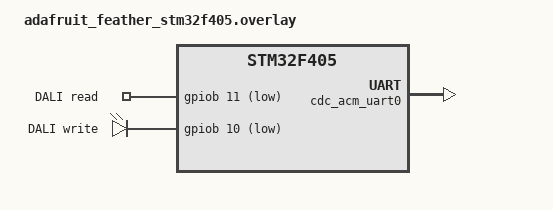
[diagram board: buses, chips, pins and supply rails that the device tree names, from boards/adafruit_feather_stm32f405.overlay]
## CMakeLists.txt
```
# SPDX-License-Identifier: Apache-2.0

cmake_minimum_required(VERSION 3.20.0)

find_package(Zephyr REQUIRED HINTS $ENV{ZEPHYR_BASE})
project(farm_light_control)

target_sources(app PRIVATE
	src/main.c
	src/dali.c
	)
```

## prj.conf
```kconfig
##################################################
## USB
##################################################
#
#CONFIG_USB_DEVICE_STACK=y
#CONFIG_USB_DEVICE_PRODUCT="zephyr_usb_logger"
#CONFIG_USB_DEVICE_PID=0x0004
#CONFIG_USB_DEVICE_INITIALIZE_AT_BOOT=n
#
##################################################
## LOGGING
##################################################
#
#CONFIG_SERIAL=y
#CONFIG_CONSOLE=y
#CONFIG_UART_CONSOLE=y
#CONFIG_UART_LINE_CTRL=y
#
#CONFIG_LOG=y
#CONFIG_LOG_MODE_IMMEDIATE=y

CONFIG_GPIO=y
```

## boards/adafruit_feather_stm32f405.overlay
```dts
/*
 * SPDX-License-Identifier: Apache-2.0
 * Copyright (c) 2023 RSA FG
 */

/ {
	chosen {
		/* zephyr,console = &cdc_acm_uart0; */
		/* zephyr,shell-uart = &cdc_acm_uart0; */
	};

	buttons {
		compatible = "gpio-keys";
		debounce-interval-ms = <250>;
		dali_rx: dali_rx {
			gpios = <&gpiob 11 GPIO_ACTIVE_LOW>;
			label = "DALI read";
		};
	};

	leds {
		compatible = "gpio-leds";
		dali_tx: dali_tx {
			gpios = <&gpiob 10 GPIO_ACTIVE_LOW>;
			label = "DALI write";
		};
	};
};

&zephyr_udc0 {
	cdc_acm_uart0: cdc_acm_uart0 {
		compatible = "zephyr,cdc-acm-uart";
	};
};
```

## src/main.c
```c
/*
 * Copyright (c) 2023 RSA FG
 *
 * SPDX-License-Identifier: Apache-2.0
 */

#include <zephyr/kernel.h>

#include <stdio.h>
#include <ctype.h>
#include <errno.h>

#include "dali.h"

#include <zephyr/logging/log.h>
LOG_MODULE_REGISTER(main, LOG_LEVEL_DBG);

int main(void)
{
	LOG_INF("starting application");

	while (1)
	{
		LOG_INF("switch off");
		dali_send_data(BROADCAST_C, OFF_C);
		k_sleep(K_SECONDS(1));

		LOG_INF("switch on");
		dali_send_data(BROADCAST_C, ON_C);
		k_sleep(K_SECONDS(1));
	}

	return 0;
}
```

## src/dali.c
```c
/*
 * Copyright (c) 2023 RSA FG
 *
 * SPDX-License-Identifier: Apache-2.0
 */

#include "dali.h"

#include <zephyr/kernel.h>
#include <zephyr/drivers/gpio.h>

#include <zephyr/logging/log.h>
LOG_MODULE_REGISTER(dali, LOG_LEVEL_DBG);

#define STOP_BITS_PERIOD K_USEC(5500)

static const struct gpio_dt_spec dali_tx = GPIO_DT_SPEC_GET(DT_NODELABEL(dali_tx), gpios);
static const struct gpio_dt_spec dali_rx = GPIO_DT_SPEC_GET(DT_NODELABEL(dali_rx), gpios);

#define HALF_BIT_PERIOD K_USEC(284)
#define QUARTER_BIT_PERIOD K_USEC(284 / 2)

#define DALI_WAIT K_MSEC(50)

#define FADE_ITERATIONS 20

static uint8_t addr;
static uint8_t command;

static uint16_t rx_buf;
static uint16_t rx_buf_rdy = 0;

static struct gpio_callback dali_cb_data;

static K_THREAD_STACK_DEFINE(dali_loop_worker_stack_area, 1024);
static struct k_thread dali_loop_worker_data;
static k_tid_t dali_loop_worker_tid = 0;

static void dali_write_bit_0(void)
{
        if (!gpio_is_ready_dt(&dali_tx)) {
		LOG_ERR("device not ready");
                return;
        }
        
	gpio_pin_configure_dt(&dali_tx, GPIO_OUTPUT_ACTIVE);
	k_sleep(HALF_BIT_PERIOD);
	gpio_pin_configure_dt(&dali_tx, GPIO_OUTPUT_INACTIVE);
	k_sleep(HALF_BIT_PERIOD);
}

static void dali_write_bit_1(void)
{
        if (!gpio_is_ready_dt(&dali_tx)) {
		LOG_ERR("device not ready");
                return;
        }
        
	gpio_pin_configure_dt(&dali_tx, GPIO_OUTPUT_INACTIVE);
	k_sleep(HALF_BIT_PERIOD);
	gpio_pin_configure_dt(&dali_tx, GPIO_OUTPUT_ACTIVE);
	k_sleep(HALF_BIT_PERIOD);
}

static void dali_write_idle(void)
{
	gpio_pin_configure_dt(&dali_tx, GPIO_OUTPUT_ACTIVE);
	k_sleep(STOP_BITS_PERIOD);
}

static void dali_write_byte(uint8_t data)
{
	uint8_t i = 0x80;

	for (i = 0x80; i > 0x00; i >>= 1)
	{
		if (data & i)
	       	{
			dali_write_bit_1();
		}
		else
		{
			dali_write_bit_0();
		}
	}
}

void dali_query(void)
{
	dali_send_data(BROADCAST_C, QUERY_STATUS);
}

void dali_on(void)
{
	dali_send_data(BROADCAST_C, ON_C);
}

void dali_off(void)
{
	dali_send_data(BROADCAST_C, OFF_C);
}

static void dali_loop_worker(void *p1, void *p2, void *p3)
{
	gpio_remove_callback(dali_rx.port, &dali_cb_data);
	dali_write_bit_1();
	dali_write_byte(*(uint8_t *)p1);
	dali_write_byte(*(uint8_t *)p2);
	dali_write_idle();
	gpio_add_callback(dali_rx.port, &dali_cb_data);

	dali_loop_worker_tid = 0;

        return;
}

void dali_send_data(uint8_t _addr, uint8_t _command)
{
	addr = _addr;
	command = _command;

	if (dali_loop_worker_tid > 0)
	{
		return;
	}

	dali_loop_worker_tid = k_thread_create(&dali_loop_worker_data,
                        dali_loop_worker_stack_area,
                        K_THREAD_STACK_SIZEOF(dali_loop_worker_stack_area),
                        dali_loop_worker,
                        &addr, &command, NULL,
                        -CONFIG_NUM_COOP_PRIORITIES, 0, K_NO_WAIT);
}

static void dali_receive(const struct device *dev, struct gpio_callback *cb,
		    uint32_t pins)
{
	static uint32_t last = 0;
	uint32_t now = k_cycle_get_32();
	uint32_t diff = now - last;

	static uint8_t received_half_bits = 0;
	static uint8_t last_bit = 1;

	if (diff > 200000)
       	{
		rx_buf = 0x00;
		rx_buf_rdy = 0;
		received_half_bits = 0;
		last_bit = 1;
	}
       	else if (diff > 105000)
	{
		rx_buf <<= 1;
		// long: bit shift
		last_bit = !last_bit;
		rx_buf |= last_bit;

		received_half_bits+=2;
		LOG_INF("long");
	}
	else
	{
		received_half_bits++;
		if (received_half_bits % 2 == 1)
		{
			rx_buf <<= 1;
			rx_buf |= last_bit;
		}
		// short: same bit
		LOG_INF("short");
	}

	if (received_half_bits >= 17)
	{
		rx_buf_rdy = 1;
		LOG_INF("received data: %hu", rx_buf & 0x00ff);
	}

	last = now;
}

int dali_receive_byte()
{
	int i;
	for (i = 0; i < 500; i++)
	{
		if (rx_buf_rdy == 1) {
			break;
		}
		k_sleep(K_MSEC(1));
	}

	if (i >= 500) {
		return -1;
	}

	rx_buf_rdy = 0;
	return rx_buf;
}

static int dali_initialize(void)
{
	int ret;

	if (!gpio_is_ready_dt(&dali_rx)) {
		LOG_ERR("Error: dali device %s is not ready\n",
		       dali_rx.port->name);
		return 0;
	}

	ret = gpio_pin_configure_dt(&dali_rx, GPIO_INPUT | GPIO_ACTIVE_LOW);
	if (ret != 0) {
		LOG_ERR("Error %d: failed to configure %s pin %d\n",
		       ret, dali_rx.port->name, dali_rx.pin);
		return 0;
	}

	ret = gpio_pin_interrupt_configure_dt(&dali_rx,
					      GPIO_INT_EDGE_BOTH);
	if (ret != 0) {
		LOG_ERR("Error %d: failed to configure interrupt on %s pin %d\n",
			ret, dali_rx.port->name, dali_rx.pin);
		return 0;
	}

	gpio_init_callback(&dali_cb_data, dali_receive, BIT(dali_rx.pin));
	gpio_add_callback(dali_rx.port, &dali_cb_data);

	LOG_INF("successfully initialized");
	return 0;
}

SYS_INIT(dali_initialize, APPLICATION, CONFIG_APPLICATION_INIT_PRIORITY);
```

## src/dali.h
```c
#ifndef DALI_H 
#define DALI_H 

#define BROADCAST_C  0xff
#define BROADCAST_P  0xfe

#define OFF_C        0x00
#define ON_C         0x05
#define QUERY_STATUS 0x90

#define DALI_C_INITIALIZE 0xa5
#define DALI_C_RANDOMIZE  0xa7
#define DALI_C_COMPARE    0xa9
#define DALI_C_WITHDRAW   0xab
#define DALI_C_PING       0xad
#define DALI_C_RESET      0x20

#include <zephyr/kernel.h>

int dali_receive_byte();
void dali_send_data(uint8_t _addr, uint8_t _command);

#endif /* DALI_H */
```

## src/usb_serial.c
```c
/*
 * Copyright (c) 2016 Intel Corporation.
 *
 * SPDX-License-Identifier: Apache-2.0
 */

#include <zephyr/kernel.h>
#include <zephyr/usb/usb_device.h>
#include <zephyr/usb/usbd.h>
#include <zephyr/drivers/uart.h>

#include <zephyr/linker/sections.h>
#include <errno.h>
#include <stdio.h>

#include <zephyr/logging/log.h>
LOG_MODULE_REGISTER(usb_serial, LOG_LEVEL_DBG);

BUILD_ASSERT(DT_NODE_HAS_COMPAT(DT_CHOSEN(zephyr_console), zephyr_cdc_acm_uart),
	     "Console device is not ACM CDC UART device");

#if defined(CONFIG_USB_DEVICE_STACK_NEXT)
USBD_CONFIGURATION_DEFINE(config_1,
			  USB_SCD_SELF_POWERED,
			  200);

USBD_DESC_LANG_DEFINE(sample_lang);
USBD_DESC_MANUFACTURER_DEFINE(sample_mfr, "ZEPHYR");
USBD_DESC_PRODUCT_DEFINE(sample_product, "Zephyr USBD ACM console");
USBD_DESC_SERIAL_NUMBER_DEFINE(sample_sn, "0123456789ABCDEF");

USBD_DEVICE_DEFINE(sample_usbd,
		   DEVICE_DT_GET(DT_NODELABEL(zephyr_udc0)),
		   0x2fe3, 0x0001);

static int enable_usb_device_next(void)
{
	int err;

	err = usbd_add_descriptor(&sample_usbd, &sample_lang);
	if (err) {
		return err;
	}

	err = usbd_add_descriptor(&sample_usbd, &sample_mfr);
	if (err) {
		return err;
	}

	err = usbd_add_descriptor(&sample_usbd, &sample_product);
	if (err) {
		return err;
	}

	err = usbd_add_descriptor(&sample_usbd, &sample_sn);
	if (err) {
		return err;
	}

	err = usbd_add_configuration(&sample_usbd, &config_1);
	if (err) {
		return err;
	}

	err = usbd_register_class(&sample_usbd, "cdc_acm_0", 1);
	if (err) {
		return err;
	}

	err = usbd_init(&sample_usbd);
	if (err) {
		return err;
	}

	err = usbd_enable(&sample_usbd);
	if (err) {
		return err;
	}

	return 0;
}
#endif /* IS_ENABLED(CONFIG_USB_DEVICE_STACK_NEXT) */

static int usb_serial_init(void)
{
	const struct device *const dev = DEVICE_DT_GET(DT_CHOSEN(zephyr_console));
	uint32_t dtr = 0;

#if defined(CONFIG_USB_DEVICE_STACK_NEXT)
	if (enable_usb_device_next()) {
		return 0;
	}
#else
	if (usb_enable(NULL)) {
		return 0;
	}
#endif

	/* Poll if the DTR flag was set */
	while (!dtr) {
		uart_line_ctrl_get(dev, UART_LINE_CTRL_DTR, &dtr);
		/* Give CPU resources to low priority threads. */
		k_sleep(K_MSEC(100));
	}

	LOG_INF("USB serial initialized %s", CONFIG_ARCH);

	return 0;
}

SYS_INIT(usb_serial_init, APPLICATION, CONFIG_APPLICATION_INIT_PRIORITY);
```

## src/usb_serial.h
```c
/*
 * Copyright (c) 2023 RSA FG
 *
 * SPDX-License-Identifier: Apache-2.0
 */
#ifndef USB_SERIAL_H 
#define USB_SERIAL_H

int usb_serial_init(void);

#endif /* USB_SERIAL_H */
```
